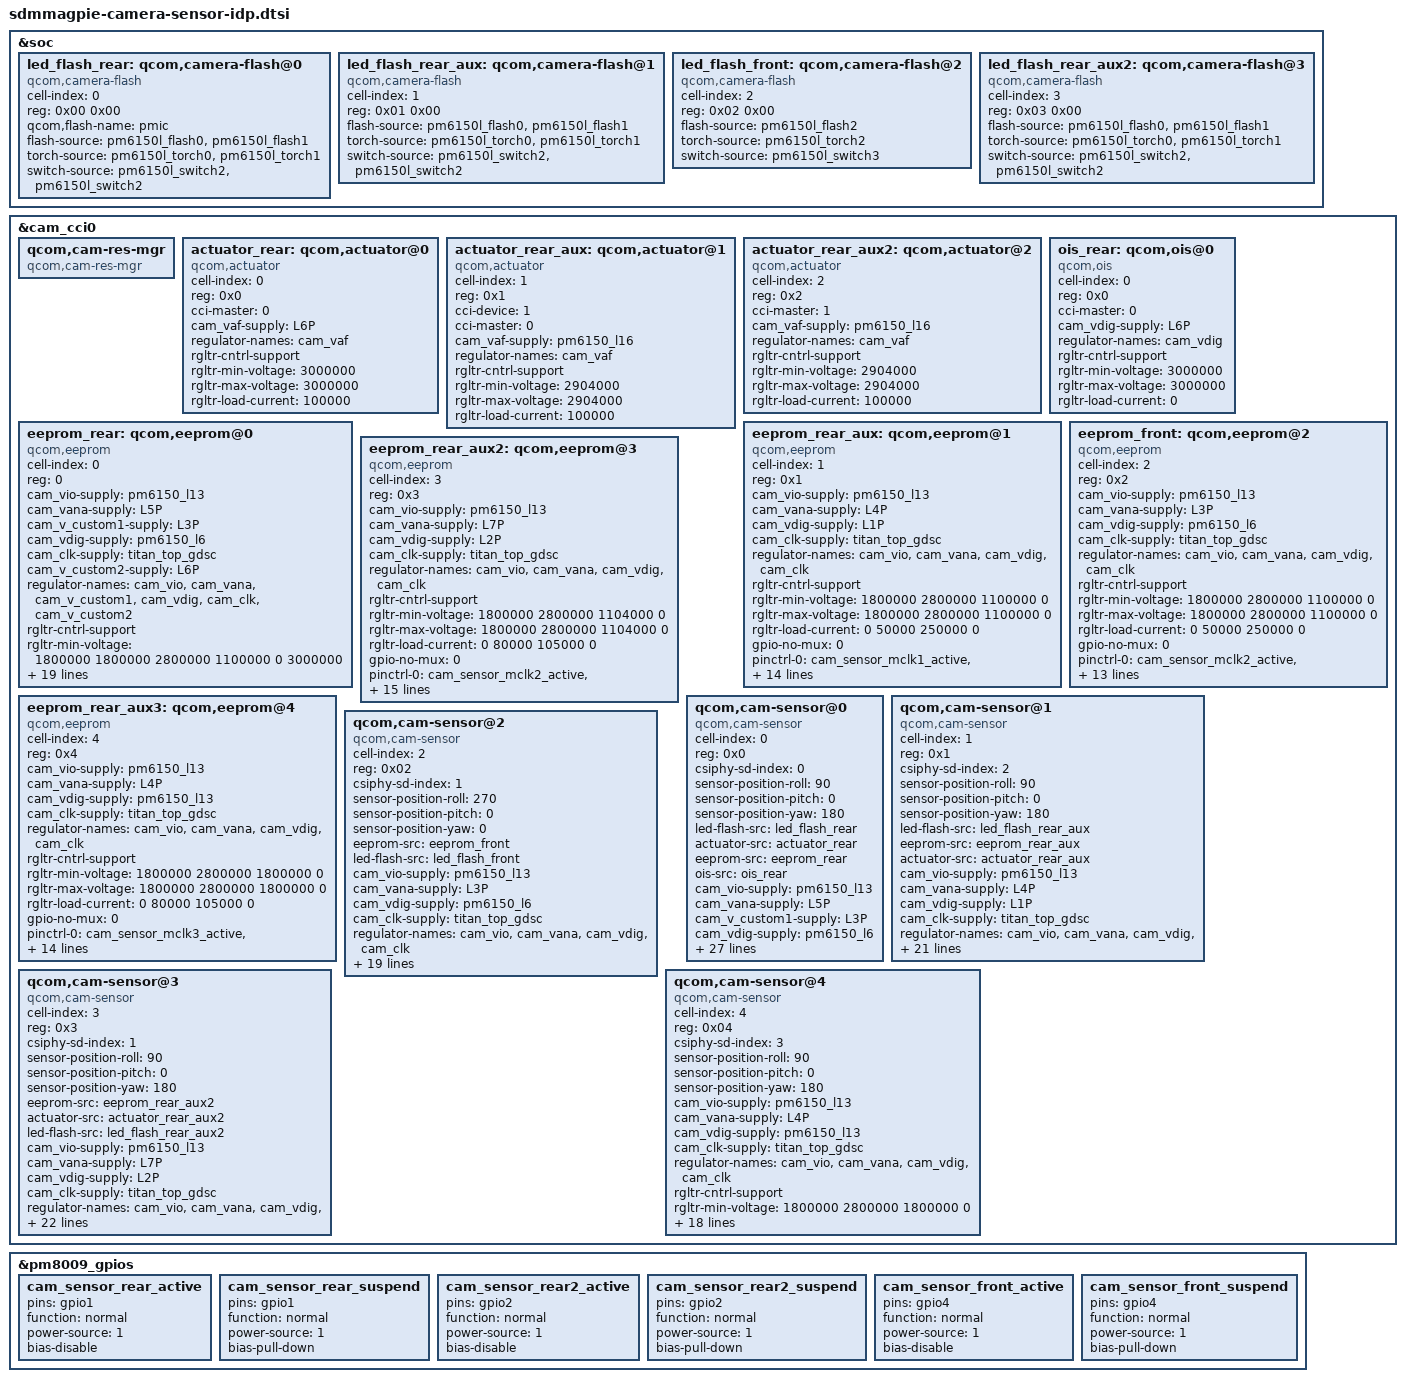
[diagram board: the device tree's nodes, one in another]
/*
 * Copyright (c) 2018-2019, The Linux Foundation. All rights reserved.
 *
 * This program is free software; you can redistribute it and/or modify
 * it under the terms of the GNU General Public License version 2 and
 * only version 2 as published by the Free Software Foundation.
 *
 * This program is distributed in the hope that it will be useful,
 * but WITHOUT ANY WARRANTY; without even the implied warranty of
 * MERCHANTABILITY or FITNESS FOR A PARTICULAR PURPOSE.  See the
 * GNU General Public License for more details.
 */
/*#ifdef VENDOR_EDIT */
#include <dt-bindings/gpio/gpio.h>
#include <dt-bindings/pinctrl/qcom,pmic-gpio.h>
/*endif */
#include <dt-bindings/clock/qcom,camcc-sdmmagpie.h>

&soc {
	led_flash_rear: qcom,camera-flash@0 {
		cell-index = <0>;
		reg = <0x00 0x00>;
		compatible = "qcom,camera-flash";
		qcom,flash-name = "pmic";
		flash-source = <&pm6150l_flash0 &pm6150l_flash1>;
		torch-source = <&pm6150l_torch0 &pm6150l_torch1>;
		switch-source = <&pm6150l_switch2 &pm6150l_switch2>;
		status = "ok";
	};

	led_flash_rear_aux: qcom,camera-flash@1 {
		cell-index = <1>;
		reg = <0x01 0x00>;
		compatible = "qcom,camera-flash";
		flash-source = <&pm6150l_flash0 &pm6150l_flash1>;
		torch-source = <&pm6150l_torch0 &pm6150l_torch1>;
		switch-source = <&pm6150l_switch2 &pm6150l_switch2>;
		status = "ok";
	};

/*#ifdef VENDOR_EDIT */
	led_flash_front: qcom,camera-flash@2 {
		cell-index = <2>;
		reg = <0x02 0x00>;
		compatible = "qcom,camera-flash";
		flash-source = <&pm6150l_flash2>;
		torch-source = <&pm6150l_torch2>;
		switch-source = <&pm6150l_switch3>;
		status = "ok";
	};
/*endif */
/*#ifdef VENDOR_EDIT */
	led_flash_rear_aux2: qcom,camera-flash@3 {
		cell-index = <3>;
		reg = <0x03 0x00>;
		compatible = "qcom,camera-flash";
		flash-source = <&pm6150l_flash0 &pm6150l_flash1>;
		torch-source = <&pm6150l_torch0 &pm6150l_torch1>;
		switch-source = <&pm6150l_switch2 &pm6150l_switch2>;
		status = "ok";
	};

/*endif */
};

/*#ifdef VENDOR_EDIT */
&cam_cci0 {
	qcom,cam-res-mgr {
		compatible = "qcom,cam-res-mgr";
		status = "ok";
	};

	actuator_rear: qcom,actuator@0 {
		cell-index = <0>;
		reg = <0x0>;
		compatible = "qcom,actuator";
		cci-master = <0>;
		cam_vaf-supply = <&L6P>;
		regulator-names = "cam_vaf";
		rgltr-cntrl-support;
		rgltr-min-voltage = <3000000>;
		rgltr-max-voltage = <3000000>;
		rgltr-load-current = <100000>;
		status = "ok";
	};

	actuator_rear_aux: qcom,actuator@1 {
		cell-index = <1>;
		reg = <0x1>;
		compatible = "qcom,actuator";
		cci-device = <1>;
		cci-master = <0>;
		cam_vaf-supply = <&pm6150_l16>;
		regulator-names = "cam_vaf";
		rgltr-cntrl-support;
		rgltr-min-voltage = <2904000>;
		rgltr-max-voltage = <2904000>;
		rgltr-load-current = <100000>;
		status = "ok";
	};

	actuator_rear_aux2: qcom,actuator@2 {
		cell-index = <2>;
		reg = <0x2>;
		compatible = "qcom,actuator";
		//cci-device = <1>;
		cci-master = <1>;
		cam_vaf-supply = <&pm6150_l16>;
		regulator-names = "cam_vaf";
		rgltr-cntrl-support;
		rgltr-min-voltage = <2904000>;
		rgltr-max-voltage = <2904000>;
		rgltr-load-current = <100000>;
		status = "ok";
	};

	ois_rear: qcom,ois@0 {
		cell-index = <0>;
		reg = <0x0>;
		compatible = "qcom,ois";
		cci-master = <0>;
		//cci-device = <0>;
		cam_vdig-supply = <&L6P>;
		regulator-names = "cam_vdig";
		rgltr-cntrl-support;
		rgltr-min-voltage = <3000000>;
		rgltr-max-voltage = <3000000>;
		rgltr-load-current = <0>;
		status = "ok";
	};
	eeprom_rear: qcom,eeprom@0 {
		cell-index = <0>;
		reg = <0>;
		compatible = "qcom,eeprom";
		cam_vio-supply = <&pm6150_l13>;
		cam_vana-supply = <&L5P>;
		cam_v_custom1-supply = <&L3P>;
		cam_vdig-supply = <&pm6150_l6>;
		cam_clk-supply = <&titan_top_gdsc>;
		cam_v_custom2-supply = <&L6P>;
		regulator-names = "cam_vio", "cam_vana", "cam_v_custom1",
			"cam_vdig", "cam_clk","cam_v_custom2";
		rgltr-cntrl-support;
		rgltr-min-voltage = <1800000 1800000 2800000 1100000 0 3000000>;
		rgltr-max-voltage = <1800000 1800000 2800000 1100000 0 3000000>;
		rgltr-load-current = <0 110000 60000 650000 0 100000>;
		gpio-no-mux = <0>;
		pinctrl-names = "cam_default", "cam_suspend";
		pinctrl-0 = <&cam_sensor_mclk0_active
				&cam_sensor_rear0_active>;
		pinctrl-1 = <&cam_sensor_mclk0_suspend
				&cam_sensor_rear0_suspend>;
		gpios = <&tlmm 13 0>,
			<&tlmm 30 0>;
		gpio-reset = <1>;
		gpio-req-tbl-num = <0 1>;
		gpio-req-tbl-flags = <1 0>;
		gpio-req-tbl-label = "CAMIF_MCLK0",
					"CAM_RESET0";
		sensor-mode = <0>;
		cci-master = <0>;
		status = "ok";
		clocks = <&clock_camcc CAM_CC_MCLK0_CLK>;
		clock-names = "cam_clk";
		clock-cntl-level = "turbo";
		clock-rates = <24000000>;
	};

	eeprom_rear_aux: qcom,eeprom@1 {
		cell-index = <1>;
		reg = <0x1>;
		compatible = "qcom,eeprom";
		cam_vio-supply = <&pm6150_l13>;
		cam_vana-supply = <&L4P>;
		cam_vdig-supply = <&L1P>;
		cam_clk-supply = <&titan_top_gdsc>;
		regulator-names = "cam_vio", "cam_vana", "cam_vdig",
			"cam_clk";
		rgltr-cntrl-support;
		rgltr-min-voltage = <1800000 2800000 1100000 0>;
		rgltr-max-voltage = <1800000 2800000 1100000 0>;
		rgltr-load-current = <0 50000 250000 0>;
		gpio-no-mux = <0>;
		pinctrl-names = "cam_default", "cam_suspend";
		pinctrl-0 = <&cam_sensor_mclk1_active
				&cam_sensor_rear21_active>;
		pinctrl-1 = <&cam_sensor_mclk1_suspend
				&cam_sensor_rear21_suspend>;
		gpios = <&tlmm 14 0>,
			<&tlmm 25 0>;
		gpio-reset = <1>;
		gpio-req-tbl-num = <0 1>;
		gpio-req-tbl-flags = <1 0>;
		gpio-req-tbl-label = "CAMIF_MCLK1",
					"CAM_RESET1";
		sensor-mode = <0>;
		cci-device = <1>;
		cci-master = <0>;
		status = "ok";
		clocks = <&clock_camcc CAM_CC_MCLK1_CLK>;
		clock-names = "cam_clk";
		clock-cntl-level = "turbo";
		clock-rates = <24000000>;
	};

	eeprom_front: qcom,eeprom@2 {
		cell-index = <2>;
		reg = <0x2>;
		compatible = "qcom,eeprom";
		cam_vio-supply = <&pm6150_l13>;
		cam_vana-supply = <&L3P>;
		cam_vdig-supply = <&pm6150_l6>;
		cam_clk-supply = <&titan_top_gdsc>;
		regulator-names = "cam_vio", "cam_vana", "cam_vdig",
			"cam_clk";
		rgltr-cntrl-support;
		rgltr-min-voltage = <1800000 2800000 1100000 0>;
		rgltr-max-voltage = <1800000 2800000 1100000 0>;
		rgltr-load-current = <0 50000 250000 0>;
		gpio-no-mux = <0>;
		pinctrl-names = "cam_default", "cam_suspend";
		pinctrl-0 = <&cam_sensor_mclk2_active
				 &cam_sensor_front0_active>;
				 //&cam_sensor_mipi_mux_active>;
		pinctrl-1 = <&cam_sensor_mclk2_suspend
				 &cam_sensor_front0_suspend>;
				 //&cam_sensor_mipi_mux_suspend>;
		gpios = <&tlmm 15 0>,
			<&tlmm 24 0>;
			//<&tlmm 43 0>;
		gpio-reset = <1>;
		gpio-req-tbl-num = <0 1>;
		gpio-req-tbl-flags = <1 0>;
		gpio-req-tbl-label = "CAMIF_MCLK2",
					"CAM_RESET2";
					//"CAM_MIPISEL";
		sensor-mode = <0>;
		//cci-device = <1>;
		cci-master = <1>;
		status = "ok";
		clocks = <&clock_camcc CAM_CC_MCLK2_CLK>;
		clock-names = "cam_clk";
		clock-cntl-level = "turbo";
		clock-rates = <24000000>;
	};

	eeprom_rear_aux2: qcom,eeprom@3 {
		cell-index = <3>;
		reg = <0x3>;
		compatible = "qcom,eeprom";
		cam_vio-supply = <&pm6150_l13>;
		cam_vana-supply = <&L7P>;
		cam_vdig-supply = <&L2P>;
		cam_clk-supply = <&titan_top_gdsc>;
		regulator-names = "cam_vio", "cam_vana", "cam_vdig",
				"cam_clk";
		rgltr-cntrl-support;
		rgltr-min-voltage = <1800000 2800000 1104000 0>;
		rgltr-max-voltage = <1800000 2800000 1104000 0>;
		rgltr-load-current = <0 80000 105000 0>;
		gpio-no-mux = <0>;
		pinctrl-names = "cam_default", "cam_suspend";
		pinctrl-0 = <&cam_sensor_mclk2_active
				 &cam_sensor_front0_active>;
				// &cam_sensor_mipi_mux_active>;
		pinctrl-1 = <&cam_sensor_mclk2_suspend
				 &cam_sensor_front0_suspend>;
				 //&cam_sensor_mipi_mux_suspend>;
		gpios = <&tlmm 15 0>,
			<&tlmm 24 0>,
			<&tlmm 43 0>;
		gpio-reset = <1>;
		gpio-custom1 = <2>;
		gpio-req-tbl-num = <0 1 2>;
		gpio-req-tbl-flags = <1 0 0>;
		gpio-req-tbl-label = "CAMIF_MCLK2",
					"CAM_RESET2",
					"CAM_CUSTOM1";
		sensor-mode = <0>;
		//cci-device = <1>;
		cci-master = <1>;
		status = "ok";
		clocks = <&clock_camcc CAM_CC_MCLK2_CLK>;
		clock-names = "cam_clk";
		clock-cntl-level = "turbo";
		clock-rates = <24000000>;
	};

	eeprom_rear_aux3: qcom,eeprom@4 {
		cell-index = <4>;
		reg = <0x4>;
		compatible = "qcom,eeprom";
		cam_vio-supply = <&pm6150_l13>;
		cam_vana-supply = <&L4P>;
		cam_vdig-supply = <&pm6150_l13>;
		cam_clk-supply = <&titan_top_gdsc>;
		regulator-names = "cam_vio", "cam_vana", "cam_vdig",
			"cam_clk";
		rgltr-cntrl-support;
		rgltr-min-voltage = <1800000 2800000 1800000 0>;
		rgltr-max-voltage = <1800000 2800000 1800000 0>;
		rgltr-load-current = <0 80000 105000 0>;
		gpio-no-mux = <0>;
		pinctrl-names = "cam_default", "cam_suspend";
		pinctrl-0 = <&cam_sensor_mclk3_active
				&cam_sensor_rear3_active>;
		pinctrl-1 = <&cam_sensor_mclk3_suspend
				&cam_sensor_rear3_suspend>;
		gpios = <&tlmm 16 0>,
			<&tlmm 23 0>;
		gpio-reset = <1>;
		gpio-req-tbl-num = <0 1>;
		gpio-req-tbl-flags = <1 0>;
		gpio-req-tbl-label = "CAMIF_MCLK3",
					"CAM_RESET3";
		sensor-mode = <0>;
		cci-device = <1>;
		cci-master = <0>;
		status = "ok";
		clocks = <&clock_camcc CAM_CC_MCLK3_CLK>;
		clock-names = "cam_clk";
		clock-cntl-level = "turbo";
		clock-rates = <24000000>;
	};

	qcom,cam-sensor@0 {
		cell-index = <0>;
		compatible = "qcom,cam-sensor";
		reg = <0x0>;
		csiphy-sd-index = <0>;
		sensor-position-roll = <90>;
		sensor-position-pitch = <0>;
		sensor-position-yaw = <180>;
		led-flash-src = <&led_flash_rear>;
		actuator-src = <&actuator_rear>;
		eeprom-src = <&eeprom_rear>;
		ois-src = <&ois_rear>;
		cam_vio-supply = <&pm6150_l13>;
		cam_vana-supply = <&L5P>;
		cam_v_custom1-supply = <&L3P>;
		cam_vdig-supply = <&pm6150_l6>;
		cam_clk-supply = <&titan_top_gdsc>;
		cam_v_custom2-supply = <&L6P>;
		regulator-names = "cam_vio", "cam_vana", "cam_v_custom1",
			"cam_vdig", "cam_clk","cam_v_custom2";
		rgltr-cntrl-support;
		rgltr-min-voltage = <1800000 1800000 2800000 1100000 0 3000000>;
		rgltr-max-voltage = <1800000 1800000 2800000 1100000 0 3000000>;
		rgltr-load-current = <0 110000 60000 650000 0 100000>;
		gpio-no-mux = <0>;
		pinctrl-names = "cam_default", "cam_suspend";
		pinctrl-0 = <&cam_sensor_mclk0_active
				&cam_sensor_rear0_active>;
		pinctrl-1 = <&cam_sensor_mclk0_suspend
				&cam_sensor_rear0_suspend>;
		gpios = <&tlmm 13 0>,
			<&tlmm 30 0>;
		gpio-reset = <1>;
		gpio-req-tbl-num = <0 1>;
		gpio-req-tbl-flags = <1 0>;
		gpio-req-tbl-label = "CAMIF_MCLK0",
					"CAM_RESET0";
		sensor-mode = <0>;
		cci-master = <0>;
		status = "ok";
		clocks = <&clock_camcc CAM_CC_MCLK0_CLK>;
		clock-names = "cam_clk";
		clock-cntl-level = "turbo";
		clock-rates = <24000000>;
	};

	qcom,cam-sensor@1 {
		cell-index = <1>;
		compatible = "qcom,cam-sensor";
		reg = <0x1>;
		csiphy-sd-index = <2>;
		sensor-position-roll = <90>;
		sensor-position-pitch = <0>;
		sensor-position-yaw = <180>;
		led-flash-src = <&led_flash_rear_aux>;
		eeprom-src = <&eeprom_rear_aux>;
		actuator-src = <&actuator_rear_aux>;
		cam_vio-supply = <&pm6150_l13>;
		cam_vana-supply = <&L4P>;
		cam_vdig-supply = <&L1P>;
		cam_clk-supply = <&titan_top_gdsc>;
		regulator-names = "cam_vio", "cam_vana", "cam_vdig",
			"cam_clk";
		rgltr-cntrl-support;
		rgltr-min-voltage = <1800000 2800000 1100000 0>;
		rgltr-max-voltage = <1800000 2800000 1100000 0>;
		rgltr-load-current = <0 50000 250000 0>;
		gpio-no-mux = <0>;
		pinctrl-names = "cam_default", "cam_suspend";
		pinctrl-0 = <&cam_sensor_mclk1_active
				&cam_sensor_rear21_active>;
		pinctrl-1 = <&cam_sensor_mclk1_suspend
				&cam_sensor_rear21_suspend>;
		gpios = <&tlmm 14 0>,
			<&tlmm 25 0>;
		gpio-reset = <1>;
		gpio-req-tbl-num = <0 1>;
		gpio-req-tbl-flags = <1 0>;
		gpio-req-tbl-label = "CAMIF_MCLK1",
					"CAM_RESET1";
		sensor-mode = <0>;
		cci-device = <1>;
		cci-master = <0>;
		status = "ok";
		clocks = <&clock_camcc CAM_CC_MCLK1_CLK>;
		clock-names = "cam_clk";
		clock-cntl-level = "turbo";
		clock-rates = <24000000>;
	};

	qcom,cam-sensor@2 {
		cell-index = <2>;
		compatible = "qcom,cam-sensor";
		reg = <0x02>;
		csiphy-sd-index = <1>;
		sensor-position-roll = <270>;
		sensor-position-pitch = <0>;
		sensor-position-yaw = <0>;
		eeprom-src = <&eeprom_front>;
		led-flash-src = <&led_flash_front>;
		cam_vio-supply = <&pm6150_l13>;
		cam_vana-supply = <&L3P>;
		cam_vdig-supply = <&pm6150_l6>;
		cam_clk-supply = <&titan_top_gdsc>;
		regulator-names = "cam_vio", "cam_vana", "cam_vdig",
			"cam_clk";
		rgltr-cntrl-support;
		rgltr-min-voltage = <1800000 2800000 1100000 0>;
		rgltr-max-voltage = <1800000 2800000 1100000 0>;
		rgltr-load-current = <0 50000 250000 0>;
		gpio-no-mux = <0>;
		pinctrl-names = "cam_default", "cam_suspend";
		pinctrl-0 = <&cam_sensor_mclk2_active
				 &cam_sensor_front0_active>;
				 //&cam_sensor_mipi_mux_active>;
		pinctrl-1 = <&cam_sensor_mclk2_suspend
				 &cam_sensor_front0_suspend>;
				 //&cam_sensor_mipi_mux_suspend>;
		gpios = <&tlmm 15 0>,
			<&tlmm 24 0>;
			//<&tlmm 43 0>;
		gpio-reset = <1>;
		gpio-req-tbl-num = <0 1>;
		gpio-req-tbl-flags = <1 0>;
		gpio-req-tbl-label = "CAMIF_MCLK2",
					"CAM_RESET2";
					//"CAM_MIPISEL";
		sensor-mode = <0>;
		//cci-device = <1>;
		cci-master = <1>;
		status = "ok";
		clocks = <&clock_camcc CAM_CC_MCLK2_CLK>;
		clock-names = "cam_clk";
		clock-cntl-level = "turbo";
		clock-rates = <24000000>;
	};

	qcom,cam-sensor@3 {
		cell-index = <3>;
		compatible = "qcom,cam-sensor";
		reg = <0x3>;
		csiphy-sd-index = <1>;
		sensor-position-roll = <90>;
		sensor-position-pitch = <0>;
		sensor-position-yaw = <180>;
		eeprom-src = <&eeprom_rear_aux2>;
		actuator-src = <&actuator_rear_aux2>;
		led-flash-src = <&led_flash_rear_aux2>;
		cam_vio-supply = <&pm6150_l13>;
		cam_vana-supply = <&L7P>;
		cam_vdig-supply = <&L2P>;
		cam_clk-supply = <&titan_top_gdsc>;
		regulator-names = "cam_vio", "cam_vana", "cam_vdig",
				"cam_clk";
		rgltr-cntrl-support;
		rgltr-min-voltage = <1800000 2800000 1104000 0>;
		rgltr-max-voltage = <1800000 2800000 1104000 0>;
		rgltr-load-current = <0 80000 105000 0>;
		gpio-no-mux = <0>;
		pinctrl-names = "cam_default", "cam_suspend";
		pinctrl-0 = <&cam_sensor_mclk2_active
				 &cam_sensor_front0_active>;
				// &cam_sensor_mipi_mux_active>;
		pinctrl-1 = <&cam_sensor_mclk2_suspend
				 &cam_sensor_front0_suspend>;
				 //&cam_sensor_mipi_mux_suspend>;
		gpios = <&tlmm 15 0>,
			<&tlmm 24 0>,
			<&tlmm 43 0>;
		gpio-reset = <1>;
		gpio-custom1 = <2>;
		gpio-req-tbl-num = <0 1 2>;
		gpio-req-tbl-flags = <1 0 0>;
		gpio-req-tbl-label = "CAMIF_MCLK2",
					"CAM_RESET2",
					"CAM_CUSTOM1";
		sensor-mode = <0>;
		//cci-device = <1>;
		cci-master = <1>;
		status = "ok";
		clocks = <&clock_camcc CAM_CC_MCLK2_CLK>;
		clock-names = "cam_clk";
		clock-cntl-level = "turbo";
		clock-rates = <24000000>;
	};

	qcom,cam-sensor@4 {
		cell-index = <4>;
		compatible = "qcom,cam-sensor";
		reg = <0x04>;
		csiphy-sd-index = <3>;
		sensor-position-roll = <90>;
		sensor-position-pitch = <0>;
		sensor-position-yaw = <180>;
		//led-flash-src = <&led_flash_rear>;
		//eeprom-src = <&eeprom_rear_aux3>;
		//actuator-src = <&actuator_rear>;
		cam_vio-supply = <&pm6150_l13>;
		cam_vana-supply = <&L4P>;
		cam_vdig-supply = <&pm6150_l13>;
		cam_clk-supply = <&titan_top_gdsc>;
		regulator-names = "cam_vio", "cam_vana", "cam_vdig",
			"cam_clk";
		rgltr-cntrl-support;
		rgltr-min-voltage = <1800000 2800000 1800000 0>;
		rgltr-max-voltage = <1800000 2800000 1800000 0>;
		rgltr-load-current = <0 80000 105000 0>;
		gpio-no-mux = <0>;
		pinctrl-names = "cam_default", "cam_suspend";
		pinctrl-0 = <&cam_sensor_mclk3_active
				&cam_sensor_rear3_active>;
		pinctrl-1 = <&cam_sensor_mclk3_suspend
				&cam_sensor_rear3_suspend>;
		gpios = <&tlmm 16 0>,
			<&tlmm 23 0>;
		gpio-reset = <1>;
		gpio-req-tbl-num = <0 1>;
		gpio-req-tbl-flags = <1 0>;
		gpio-req-tbl-label = "CAMIF_MCLK3",
					"CAM_RESET3";
		sensor-mode = <0>;
		cci-device = <1>;
		cci-master = <0>;
		status = "ok";
		clocks = <&clock_camcc CAM_CC_MCLK3_CLK>;
		clock-names = "cam_clk";
		clock-cntl-level = "turbo";
		clock-rates = <24000000>;
	};
};
/*endif */

&pm8009_gpios {
	cam_sensor_rear_active: cam_sensor_rear_active {
		pins = "gpio1";
		function = "normal";
		power-source = <1>;
		bias-disable;
	};
	cam_sensor_rear_suspend: cam_sensor_rear_suspend {
		pins = "gpio1";
		function = "normal";
		power-source = <1>;
		bias-pull-down;
	};

	cam_sensor_rear2_active: cam_sensor_rear2_active {
		pins = "gpio2";
		function = "normal";
		power-source = <1>;
		bias-disable;
	};
	cam_sensor_rear2_suspend: cam_sensor_rear2_suspend {
		pins = "gpio2";
		function = "normal";
		power-source = <1>;
		bias-pull-down;
	};

	cam_sensor_front_active: cam_sensor_front_active {
		pins = "gpio4";
		function = "normal";
		power-source = <1>;
		bias-disable;
	};
	cam_sensor_front_suspend: cam_sensor_front_suspend {
		pins = "gpio4";
		function = "normal";
		power-source = <1>;
		bias-pull-down;
	};
};
